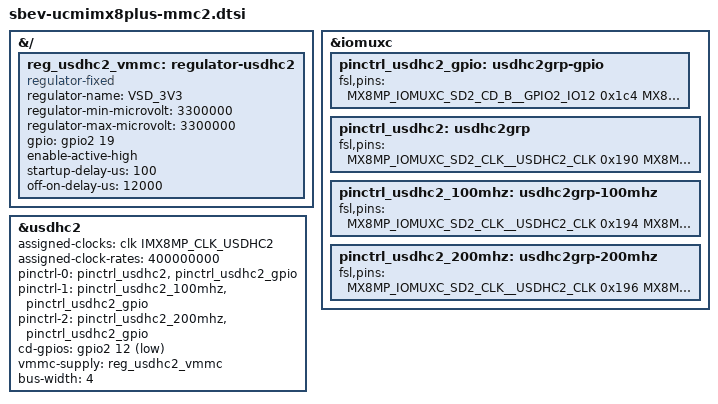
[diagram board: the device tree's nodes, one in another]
// SPDX-License-Identifier: (GPL-2.0+ OR MIT)
/*
 * Copyright 2024 CompuLab LTD.
 */

&{/} {
	reg_usdhc2_vmmc: regulator-usdhc2 {
		compatible = "regulator-fixed";
		regulator-name = "VSD_3V3";
		regulator-min-microvolt = <3300000>;
		regulator-max-microvolt = <3300000>;
		gpio = <&gpio2 19 GPIO_ACTIVE_HIGH>;
		enable-active-high;
		startup-delay-us = <100>;
		off-on-delay-us = <12000>;
	};
};

&iomuxc {
	pinctrl_usdhc2_gpio: usdhc2grp-gpio {
		fsl,pins = <
			MX8MP_IOMUXC_SD2_CD_B__GPIO2_IO12	0x1c4
			MX8MP_IOMUXC_SD2_RESET_B__GPIO2_IO19	0x41
		>;
	};

	pinctrl_usdhc2: usdhc2grp {
		fsl,pins = <
			MX8MP_IOMUXC_SD2_CLK__USDHC2_CLK	0x190
			MX8MP_IOMUXC_SD2_CMD__USDHC2_CMD	0x1d0
			MX8MP_IOMUXC_SD2_DATA0__USDHC2_DATA0	0x1d0
			MX8MP_IOMUXC_SD2_DATA1__USDHC2_DATA1	0x1d0
			MX8MP_IOMUXC_SD2_DATA2__USDHC2_DATA2	0x1d0
			MX8MP_IOMUXC_SD2_DATA3__USDHC2_DATA3	0x1d0
			MX8MP_IOMUXC_GPIO1_IO04__USDHC2_VSELECT	0xc1
		>;
	};

	pinctrl_usdhc2_100mhz: usdhc2grp-100mhz {
		fsl,pins = <
			MX8MP_IOMUXC_SD2_CLK__USDHC2_CLK	0x194
			MX8MP_IOMUXC_SD2_CMD__USDHC2_CMD	0x1d4
			MX8MP_IOMUXC_SD2_DATA0__USDHC2_DATA0	0x1d4
			MX8MP_IOMUXC_SD2_DATA1__USDHC2_DATA1	0x1d4
			MX8MP_IOMUXC_SD2_DATA2__USDHC2_DATA2	0x1d4
			MX8MP_IOMUXC_SD2_DATA3__USDHC2_DATA3	0x1d4
			MX8MP_IOMUXC_GPIO1_IO04__USDHC2_VSELECT 0xc1
		>;
	};

	pinctrl_usdhc2_200mhz: usdhc2grp-200mhz {
		fsl,pins = <
			MX8MP_IOMUXC_SD2_CLK__USDHC2_CLK	0x196
			MX8MP_IOMUXC_SD2_CMD__USDHC2_CMD	0x1d6
			MX8MP_IOMUXC_SD2_DATA0__USDHC2_DATA0	0x1d6
			MX8MP_IOMUXC_SD2_DATA1__USDHC2_DATA1	0x1d6
			MX8MP_IOMUXC_SD2_DATA2__USDHC2_DATA2	0x1d6
			MX8MP_IOMUXC_SD2_DATA3__USDHC2_DATA3	0x1d6
			MX8MP_IOMUXC_GPIO1_IO04__USDHC2_VSELECT 0xc1
		>;
	};

};

&usdhc2 {
	assigned-clocks = <&clk IMX8MP_CLK_USDHC2>;
	assigned-clock-rates = <400000000>;
	pinctrl-names = "default", "state_100mhz", "state_200mhz";
	pinctrl-0 = <&pinctrl_usdhc2>, <&pinctrl_usdhc2_gpio>;
	pinctrl-1 = <&pinctrl_usdhc2_100mhz>, <&pinctrl_usdhc2_gpio>;
	pinctrl-2 = <&pinctrl_usdhc2_200mhz>, <&pinctrl_usdhc2_gpio>;
	cd-gpios = <&gpio2 12 GPIO_ACTIVE_LOW>;
	vmmc-supply = <&reg_usdhc2_vmmc>;
	bus-width = <4>;
	status = "okay";
};
